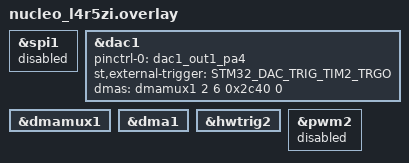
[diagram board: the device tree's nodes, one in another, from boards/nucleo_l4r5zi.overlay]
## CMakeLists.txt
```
# SPDX-License-Identifier: Apache-2.0

cmake_minimum_required(VERSION 3.13.1)

find_package(Zephyr REQUIRED HINTS $ENV{ZEPHYR_BASE})
project(DAC_ASYNC)

target_sources(app PRIVATE src/main.c)
```

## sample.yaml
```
sample:
  name: DAC async driver sample
tests:
  sample.drivers.dac:
    tags: DAC
    platform_allow: |
      nucleo_l4r5zi
    depends_on: dac
    harness: console
    harness_config:
      type: one_line
      regex:
        - "Generating sawtooth signal at DAC channel ([0-9]*)."
```

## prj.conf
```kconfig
# SPDX-License-Identifier: Apache-2.0

CONFIG_DAC=y
CONFIG_DAC_CONTINUOUS_API=y
CONFIG_HWTRIG=y
CONFIG_DMA=y
```

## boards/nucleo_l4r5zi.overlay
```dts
/*
 * SPDX-License-Identifier: Apache-2.0
 */

#include <dt-bindings/dac/stm32_dac.h>

/* dac needs pa4 */
&spi1 {
	status = "disabled";
};

&dac1 {
	status = "okay";
	pinctrl-0 = <&dac1_out1_pa4>;
	st,external-trigger = <STM32_DAC_TRIG_TIM2_TRGO>;
	dmas = <&dmamux1 2 6 0x2c40 0>;
	dma-names = "channel1";
};

&dmamux1 {
	status = "okay";
};

&dma1 {
	status = "okay";
};

&hwtrig2 {
	status = "okay";
};

&pwm2 {
	status = "disabled";
};
```

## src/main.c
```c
/*
 * Copyright (c) 2020 Libre Solar Technologies GmbH
 *
 * SPDX-License-Identifier: Apache-2.0
 */

#include <zephyr.h>
#include <sys/printk.h>
#include <drivers/dac.h>
#include <drivers/hwtrig.h>

#if defined(CONFIG_BOARD_NUCLEO_L4R5ZI)
#define DAC_DEVICE_NAME		DT_LABEL(DT_NODELABEL(dac1))
#define HWTRIG_DEVICE_NAME	DT_LABEL(DT_NODELABEL(hwtrig2))
#define DAC_CHANNEL_ID		1
#define DAC_RESOLUTION		12
#else
#error "Unsupported board."
#endif

static const struct dac_channel_cfg dac_ch_cfg = {
	.channel_id  = DAC_CHANNEL_ID,
	.resolution  = DAC_RESOLUTION,
	.enable_hw_trigger = true
};

static uint16_t dac_values[1 << DAC_RESOLUTION];
static uint16_t curr_values_pos = 0;

static void fill_dac_buffer(const struct device *dev_dac, uint8_t channel)
{
	int ret;
	while (true)
	{
		size_t size = (ARRAY_SIZE(dac_values) - curr_values_pos) * 2;
		ret = dac_fill_buffer(dev_dac, channel,
				(uint8_t *)&dac_values[curr_values_pos], size);

		curr_values_pos =
				(curr_values_pos + (ret / 2)) % ARRAY_SIZE(dac_values);
		if (ret < size) {
			return;
		}
	}
}

void dac_callback(const struct device *dev_dac, uint8_t channel, void *arg)
{
	if (channel == 1) {
		fill_dac_buffer(dev_dac, channel);
	}
}

void main(void)
{
	const struct device *dac_dev = device_get_binding(DAC_DEVICE_NAME);
	const struct device *hwtrig_dev = device_get_binding(HWTRIG_DEVICE_NAME);

	if (!dac_dev) {
		printk("Cannot get DAC device\n");
		return;
	}

	if (!hwtrig_dev) {
		printk("Cannot get HWTRIG device\n");
		return;
	}

	for (uint16_t i = 0; i < ARRAY_SIZE(dac_values); ++i) {
		dac_values[i] = i;
	}

	int ret = dac_channel_setup(dac_dev, &dac_ch_cfg);

	if (ret != 0) {
		printk("Setting up of DAC channel failed with code %d\n", ret);
		return;
	}

	dac_callback_set(dac_dev, dac_callback, NULL);

	dac_start_continuous(dac_dev, DAC_CHANNEL_ID);
	fill_dac_buffer(dac_dev, DAC_CHANNEL_ID);

	printk("Generating sawtooth signal at DAC channel %d.\n",
		DAC_CHANNEL_ID);

	uint32_t freq = 1000; // 1 [KHz]
	hwtrig_enable(hwtrig_dev, &freq);
}
```
